VERSION ""

NS_ :

BS_:

BU_:

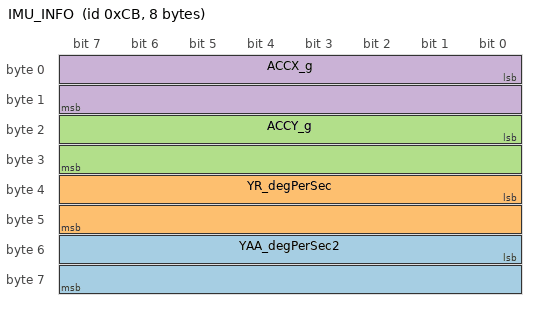
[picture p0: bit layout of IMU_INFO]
BO_ 203 IMU_INFO: 8 Vector__XXX
 SG_ YAA_degPerSec2 : 48|16@1- (0.01,0) [-327.68|327.67] "deg/s^2" Vector__XXX
 SG_ YR_degPerSec : 32|16@1- (0.01,0) [-327.68|327.67] "deg/s" Vector__XXX
 SG_ ACCY_g : 16|16@1- (0.01,0) [-327.68|327.67] "g" Vector__XXX
 SG_ ACCX_g : 0|16@1- (0.01,0) [-327.68|327.67] "g" Vector__XXX

BA_DEF_  "BusType" STRING ;
BA_DEF_DEF_  "BusType" "CAN";
